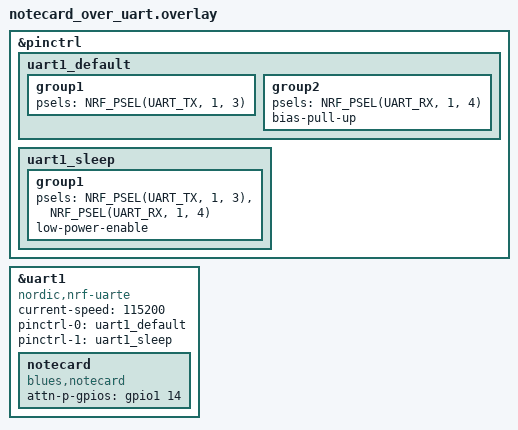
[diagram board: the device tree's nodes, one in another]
&pinctrl {
	uart1_default: uart1_default {
		group1 {
			psels = <NRF_PSEL(UART_TX, 1, 3)>;
		};
		group2 {
			psels = <NRF_PSEL(UART_RX, 1, 4)>;
			bias-pull-up;
		};
	};

	uart1_sleep: uart1_sleep {
		group1 {
			psels = <NRF_PSEL(UART_TX, 1, 3)>,
				<NRF_PSEL(UART_RX, 1, 4)>;
			low-power-enable;
		};
	};
};

&uart1 {
	compatible = "nordic,nrf-uarte";
	current-speed = <115200>;
	pinctrl-0 = <&uart1_default>;
	pinctrl-1 = <&uart1_sleep>;
	pinctrl-names = "default", "sleep";
	status = "okay";

	notecard: notecard {
		compatible = "blues,notecard";
		attn-p-gpios = <&gpio1 14 (GPIO_ACTIVE_HIGH | GPIO_PULL_DOWN)>;
	};
};
